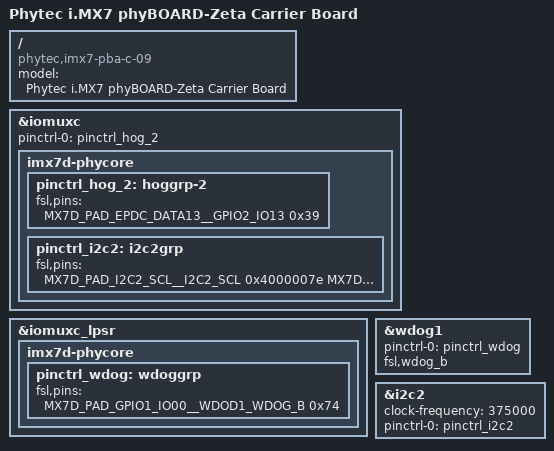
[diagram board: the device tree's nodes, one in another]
/*
 * Copyright (C) 2015 PHYTEC America, LLC
 *
 * This program is free software; you can redistribute it and/or modify
 * it under the terms of the GNU General Public License version 2 as
 * published by the Free Software Foundation.
 */

/ {
	model = "Phytec i.MX7 phyBOARD-Zeta Carrier Board";
	compatible = "phytec,imx7-pba-c-09", "phytec,imx7-phycore-som", "fsl,imx7d";
};

&iomuxc {
	pinctrl-names = "default";
	pinctrl-0 = <&pinctrl_hog_2>;

	imx7d-phycore {
		pinctrl_hog_2: hoggrp-2 {
			fsl,pins = <
				MX7D_PAD_EPDC_DATA13__GPIO2_IO13	0x39 /* Boot Circuit Buffer Enable
										5K pull-up  */
			>;
		};
	};
};

&iomuxc_lpsr {
	pinctrl-names = "default";

	imx7d-phycore {
		pinctrl_wdog: wdoggrp {
			fsl,pins = <
				MX7D_PAD_GPIO1_IO00__WDOD1_WDOG_B	0x74
			>;
		};
	};
};

&wdog1 {
	pinctrl-names = "default";
	pinctrl-0 = <&pinctrl_wdog>;
	fsl,wdog_b;
	status = "okay";
};

&iomuxc {
	imx7d-phycore {
		pinctrl_i2c2: i2c2grp {
			fsl,pins = <
				MX7D_PAD_I2C2_SCL__I2C2_SCL		0x4000007e
				MX7D_PAD_I2C2_SDA__I2C2_SDA		0x4000007e
			>;
		};
	};
};

&i2c2 {
	clock-frequency = <375000>;
	pinctrl-names = "default";
	pinctrl-0 = <&pinctrl_i2c2>;
	status = "okay";
};
